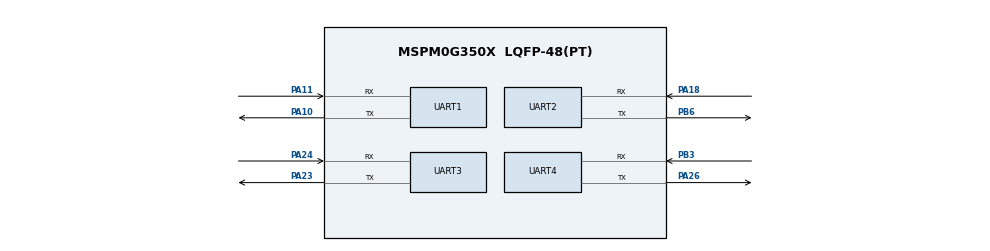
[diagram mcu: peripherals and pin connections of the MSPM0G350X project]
/**
 * @cliArgs --device "MSPM0G350X" --part "Default" --package "LQFP-48(PT)" --product "mspm0_sdk@2.10.00.04"
 * @versions {"tool":"1.26.2+4477"}
 */

/**
 * Import the modules used in this configuration.
 */
const GPIO   = scripting.addModule("/ti/driverlib/GPIO", {}, false);
const GPIO1  = GPIO.addInstance();
const SYSCTL = scripting.addModule("/ti/driverlib/SYSCTL");
const UART   = scripting.addModule("/ti/driverlib/UART", {}, false);
const UART1  = UART.addInstance();
const UART2  = UART.addInstance();
const UART3  = UART.addInstance();
const UART4  = UART.addInstance();

/**
 * Write custom configuration values to the imported modules.
 */
const divider9       = system.clockTree["UDIV"];
divider9.divideValue = 2;

const multiplier2         = system.clockTree["PLL_QDIV"];
multiplier2.multiplyValue = 20;

const mux2       = system.clockTree["CANCLKMUX"];
mux2.inputSelect = "CANCLKMUX_PLLCLK1_OUT";

const mux4       = system.clockTree["EXHFMUX"];
mux4.inputSelect = "EXHFMUX_XTAL";

const mux8       = system.clockTree["HSCLKMUX"];
mux8.inputSelect = "HSCLKMUX_SYSPLL0";

const mux12       = system.clockTree["SYSPLLMUX"];
mux12.inputSelect = "zSYSPLLMUX_HFCLK";

const pinFunction4     = system.clockTree["HFXT"];
pinFunction4.inputFreq = 8;
pinFunction4.enable    = true;

GPIO1.$name                              = "IIC";
GPIO1.associatedPins.create(2);
GPIO1.associatedPins[0].$name            = "SDA";
GPIO1.associatedPins[0].initialValue     = "SET";
GPIO1.associatedPins[0].internalResistor = "PULL_UP";
GPIO1.associatedPins[1].$name            = "SCL";
GPIO1.associatedPins[1].initialValue     = "SET";
GPIO1.associatedPins[1].internalResistor = "PULL_UP";

const Board = scripting.addModule("/ti/driverlib/Board", {}, false);

SYSCTL.clockTreeEn           = true;
SYSCTL.forceDefaultClkConfig = true;
SYSCTL.validateClkStatus     = true;

UART1.$name                    = "UART_0";
UART1.peripheral.$assign       = "UART0";
UART1.peripheral.rxPin.$assign = "PA11";
UART1.peripheral.txPin.$assign = "PA10";
UART1.txPinConfig.$name        = "ti_driverlib_gpio_GPIOPinGeneric0";
UART1.rxPinConfig.$name        = "ti_driverlib_gpio_GPIOPinGeneric1";

UART2.$name                    = "UART_1";
UART2.peripheral.$assign       = "UART1";
UART2.peripheral.rxPin.$assign = "PA18";
UART2.peripheral.txPin.$assign = "PB6";
UART2.txPinConfig.$name        = "ti_driverlib_gpio_GPIOPinGeneric2";
UART2.rxPinConfig.$name        = "ti_driverlib_gpio_GPIOPinGeneric3";

UART3.$name                    = "UART_2";
UART3.peripheral.$assign       = "UART2";
UART3.peripheral.rxPin.$assign = "PA24";
UART3.peripheral.txPin.$assign = "PA23";
UART3.txPinConfig.$name        = "ti_driverlib_gpio_GPIOPinGeneric4";
UART3.rxPinConfig.$name        = "ti_driverlib_gpio_GPIOPinGeneric5";

UART4.$name                    = "UART_3";
UART4.peripheral.$assign       = "UART3";
UART4.peripheral.rxPin.$assign = "PB3";
UART4.peripheral.txPin.$assign = "PA26";
UART4.txPinConfig.$name        = "ti_driverlib_gpio_GPIOPinGeneric6";
UART4.rxPinConfig.$name        = "ti_driverlib_gpio_GPIOPinGeneric7";

/**
 * Pinmux solution for unlocked pins/peripherals. This ensures that minor changes to the automatic solver in a future
 * version of the tool will not impact the pinmux you originally saw.  These lines can be completely deleted in order to
 * re-solve from scratch.
 */
pinFunction4.peripheral.$suggestSolution           = "SYSCTL";
pinFunction4.peripheral.hfxInPin.$suggestSolution  = "PA5";
pinFunction4.peripheral.hfxOutPin.$suggestSolution = "PA6";
GPIO1.associatedPins[0].pin.$suggestSolution       = "PA0";
GPIO1.associatedPins[1].pin.$suggestSolution       = "PA1";
Board.peripheral.$suggestSolution                  = "DEBUGSS";
Board.peripheral.swclkPin.$suggestSolution         = "PA20";
Board.peripheral.swdioPin.$suggestSolution         = "PA19";
